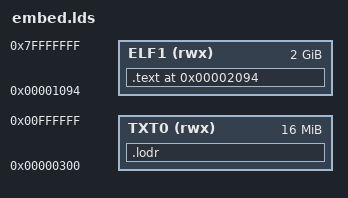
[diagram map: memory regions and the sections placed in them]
/* s390 Stand-Alone Linker Script      
   Generated by ipldpp.py - DO NOT EDIT */

OUTPUT_FORMAT(elf32-s390)
OUTPUT_ARCH(s390:31-bit)
TARGET(elf32-s390)
ENTRY(_start)

MEMORY
{
    ELF1 (rwx) : ORIGIN = 0x1094, LENGTH = 0x7FFFEF6C
    TXT0 (rwx) : ORIGIN = 0x300, LENGTH = 0xFFFD00
}

PHDRS
{
    TEXT PT_LOAD    FLAGS ( 0x00000007 ) ;
    LODR PT_LOAD    FLAGS ( 0xF0000007 ) ;
}

SECTIONS
{
    .text 0x2094  :    
    {
        . = ALIGN(16) ;
        *(.text)
        . = ALIGN(16) ;
        *(.data)
        . = ALIGN(16) ;
        PROVIDE(_GOT_begin = .);
        *(.got)
        PROVIDE(_GOT_end = .);
        . = ALIGN(16) ;
        *(.shstrtab)
        . = ALIGN(16) ;
        *(.symtab)
        . = ALIGN(16) ;
        *(.strtab)
        . = ALIGN(16) ;
        *(.rela.text)
        . = ALIGN(16) ;
        *(.bss)
    } >ELF1  :TEXT

    .lodr   :    
    {
        *(.loader)
    } >TXT0  :LODR

    /DISCARD/   :    
    {
        *(.rela.loader)
    }   

}

